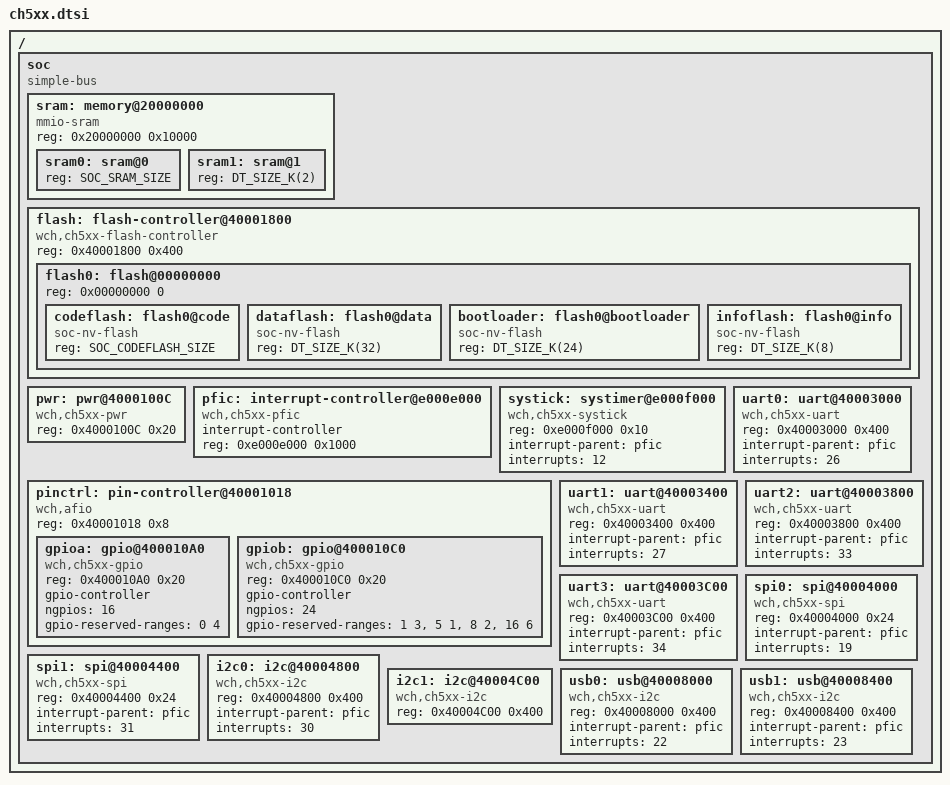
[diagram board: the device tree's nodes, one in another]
/*
 * Copyright (c) 2026 Mike Kasprzak (distraction.engineer)
 *
 * SPDX-License-Identifier: Apache-2.0
 */

// 0x40001000 - watchdog
// 0x40001008 - system clock
// 0x4000100C - power

#include <freq.h>
#include <mem.h>

#ifndef SOC_SRAM_SIZE
#error "SOC_SRAM_SIZE is required"
#endif /* SOC_SRAM_SIZE */

#ifndef SOC_CODEFLASH_SIZE
#error "SOC_CODEFLASH_SIZE is required"
#endif /* SOC_CODEFLASH_SIZE */

/ {
	soc {
		#address-cells = <1>;
		#size-cells = <1>;
		compatible = "simple-bus";
		ranges;

		sram: memory@20000000 {
			compatible = "mmio-sram";
			reg = <0x20000000 0x10000>;
			#size-cells = <0>;

			sram0: sram@0 {
				reg = <SOC_SRAM_SIZE>;
			};
			sram1: sram@1 {
				reg = <DT_SIZE_K(2)>;
			};
		};

		flash: flash-controller@40001800 {
			compatible = "wch,ch5xx-flash-controller";
			reg = <0x40001800 0x400>;
			#address-cells = <1>;
			#size-cells = <1>;

			flash0: flash@00000000 {
				reg = <0x00000000 0>;

				codeflash: flash0@code {
					compatible = "soc-nv-flash";
					reg = <SOC_CODEFLASH_SIZE>;
				};
				dataflash: flash0@data {
					compatible = "soc-nv-flash";
					reg = <DT_SIZE_K(32)>;
				};
				bootloader: flash0@bootloader {
					compatible = "soc-nv-flash";
					reg = <DT_SIZE_K(24)>;
				};
				infoflash: flash0@info {
					compatible = "soc-nv-flash";
					reg = <DT_SIZE_K(8)>;
				};
			};
		};

		pwr: pwr@4000100C {
			compatible = "wch,ch5xx-pwr";
			reg = <0x4000100C 0x20>;
		};

		pfic: interrupt-controller@e000e000 {
			compatible = "wch,ch5xx-pfic";
			#address-cells = <0>;
			#interrupt-cells = <1>;
			interrupt-controller;
			reg = <0xe000e000 0x1000>;
			status = "okay";
		};

		systick: systimer@e000f000 {
			compatible = "wch,ch5xx-systick";
			reg = <0xe000f000 0x10>;
			status = "okay";
			interrupt-parent = <&pfic>;
			interrupts = <12>;
		};

		pinctrl: pin-controller@40001018 {
			compatible = "wch,afio";
			reg = <0x40001018 0x8>;
			#address-cells = <1>;
			#size-cells = <1>;

			gpioa: gpio@400010A0 {
				compatible = "wch,ch5xx-gpio";
				reg = <0x400010A0 0x20>;
				gpio-controller;
				#gpio-cells = <2>;
				ngpios = <16>;
				gpio-reserved-ranges = <0 4>;
			};
			gpiob: gpio@400010C0 {
				compatible = "wch,ch5xx-gpio";
				reg = <0x400010C0 0x20>;
				gpio-controller;
				#gpio-cells = <2>;
				ngpios = <24>;
				gpio-reserved-ranges = <1 3>, <5 1>, <8 2>, <16 6>;
			};

		};

		uart0: uart@40003000 {
			compatible = "wch,ch5xx-uart";
			reg = <0x40003000 0x400>;
			interrupt-parent = <&pfic>;
			interrupts = <26>;
		};
		uart1: uart@40003400 {
			compatible = "wch,ch5xx-uart";
			reg = <0x40003400 0x400>;
			interrupt-parent = <&pfic>;
			interrupts = <27>;
		};
		uart2: uart@40003800 {
			compatible = "wch,ch5xx-uart";
			reg = <0x40003800 0x400>;
			interrupt-parent = <&pfic>;
			interrupts = <33>;
		};
		uart3: uart@40003C00 {
			compatible = "wch,ch5xx-uart";
			reg = <0x40003C00 0x400>;
			interrupt-parent = <&pfic>;
			interrupts = <34>;
		};

		spi0: spi@40004000 {
			compatible = "wch,ch5xx-spi";
			reg = <0x40004000 0x24>;
			interrupt-parent = <&pfic>;
			interrupts = <19>;
		};
		// PWM4-11, SPI1
		spi1: spi@40004400 {
			compatible = "wch,ch5xx-spi";
			reg = <0x40004400 0x24>;
			interrupt-parent = <&pfic>;
			interrupts = <31>;
		};

		i2c0: i2c@40004800 {
			compatible = "wch,ch5xx-i2c";
			reg = <0x40004800 0x400>;
			interrupt-parent = <&pfic>;
			interrupts = <30>;
		};
		i2c1: i2c@40004C00 {
			compatible = "wch,ch5xx-i2c";
			reg = <0x40004C00 0x400>;
		};

		usb0: usb@40008000 {
			compatible = "wch,ch5xx-i2c";
			reg = <0x40008000 0x400>;
			interrupt-parent = <&pfic>;
			interrupts = <22>;
		};
		usb1: usb@40008400 {
			compatible = "wch,ch5xx-i2c";
			reg = <0x40008400 0x400>;
			interrupt-parent = <&pfic>;
			interrupts = <23>;
		};

	};
};
